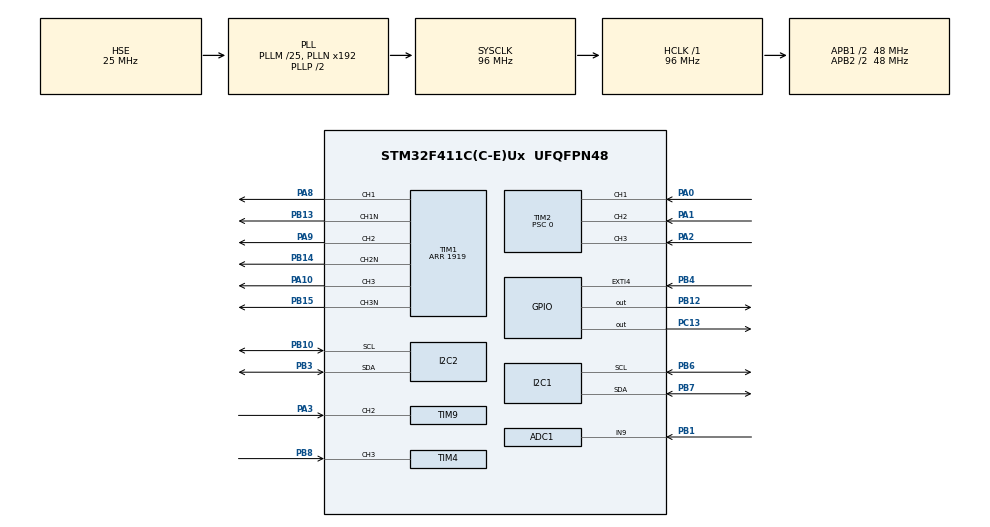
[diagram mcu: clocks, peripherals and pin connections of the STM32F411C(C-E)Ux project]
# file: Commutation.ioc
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ADC1.Channel-0\#ChannelRegularConversion=ADC_CHANNEL_9
ADC1.ExternalTrigConv=ADC_EXTERNALTRIGCONV_T3_TRGO
ADC1.NbrOfConversionFlag=1
ADC1.Rank-0\#ChannelRegularConversion=1
ADC1.SamplingTime-0\#ChannelRegularConversion=ADC_SAMPLETIME_15CYCLES
ADC1.master=1
I2C1.NoStretchMode=I2C_NOSTRETCH_DISABLE
I2C1.OwnAddress=0x10
Mcu.Family=STM32F4
Mcu.Name=STM32F411C(C-E)Ux
Mcu.Package=UFQFPN48
NVIC.ADC_IRQn=true\:0\:0\:false\:false\:true\:true\:true\:true
NVIC.EXTI4_IRQn=true\:0\:0\:false\:false\:true\:true\:true\:true
NVIC.I2C1_ER_IRQn=true\:0\:0\:false\:false\:true\:true\:true\:true
NVIC.I2C1_EV_IRQn=true\:0\:0\:false\:false\:true\:true\:true\:true
NVIC.PriorityGroup=NVIC_PRIORITYGROUP_4
NVIC.TIM1_BRK_TIM9_IRQn=true\:0\:0\:false\:false\:true\:true\:true\:true
NVIC.TIM1_TRG_COM_TIM11_IRQn=true\:0\:0\:false\:false\:true\:true\:true\:true
NVIC.TIM1_UP_TIM10_IRQn=true\:0\:0\:false\:false\:true\:true\:true\:true
NVIC.TIM2_IRQn=true\:0\:0\:false\:false\:true\:true\:true\:true
NVIC.TIM3_IRQn=true\:0\:0\:false\:false\:true\:true\:true\:true
NVIC.TIM5_IRQn=true\:0\:0\:false\:false\:true\:true\:true\:true
PA0-WKUP.GPIO_PuPd=GPIO_PULLUP
PA0-WKUP.Signal=S_TIM2_CH1_ETR
PA1.GPIO_PuPd=GPIO_PULLUP
PA1.Signal=S_TIM2_CH2
PA10.GPIO_PuPd=GPIO_NOPULL
PA10.Signal=S_TIM1_CH3
PA13.Mode=Serial_Wire
PA13.Signal=SYS_JTMS-SWDIO
PA14.Mode=Serial_Wire
PA14.Signal=SYS_JTCK-SWCLK
PA2.GPIO_PuPd=GPIO_PULLUP
PA2.Signal=S_TIM2_CH3
PA3.GPIO_PuPd=GPIO_PULLUP
PA3.Signal=S_TIM9_CH2
PA8.GPIO_PuPd=GPIO_NOPULL
PA8.Signal=S_TIM1_CH1
PA9.GPIO_PuPd=GPIO_NOPULL
PA9.Signal=S_TIM1_CH2
PB1.Signal=ADCx_IN9
PB10.GPIO_Pu=GPIO_PULLUP
PB10.Mode=I2C
PB10.Signal=I2C2_SCL
PB12.Signal=GPIO_Output
PB13.GPIO_PuPd=GPIO_NOPULL
PB13.Mode=PWM Generation1 CH1 CH1N
PB13.Signal=TIM1_CH1N
PB14.GPIO_PuPd=GPIO_NOPULL
PB14.Mode=PWM Generation2 CH2 CH2N
PB14.Signal=TIM1_CH2N
PB15.GPIO_PuPd=GPIO_NOPULL
PB15.Mode=PWM Generation3 CH3 CH3N
PB15.Signal=TIM1_CH3N
PB3.GPIO_Pu=GPIO_PULLUP
PB3.Mode=I2C
PB3.Signal=I2C2_SDA
PB4.GPIO_ModeDefaultEXTI=GPIO_MODE_IT_FALLING
PB4.GPIO_PuPd=GPIO_PULLDOWN
PB4.Signal=GPXTI4
PB6.GPIO_Pu=GPIO_PULLUP
PB6.Mode=I2C
PB6.Signal=I2C1_SCL
PB7.GPIO_Pu=GPIO_PULLUP
PB7.Mode=I2C
PB7.Signal=I2C1_SDA
PB8.Signal=S_TIM4_CH3
PC13-ANTI_TAMP.Signal=GPIO_Output
PH0\ -\ OSC_IN.Mode=HSE-External-Oscillator
PH0\ -\ OSC_IN.Signal=RCC_OSC_IN
PH1\ -\ OSC_OUT.Mode=HSE-External-Oscillator
PH1\ -\ OSC_OUT.Signal=RCC_OSC_OUT
ProjectManager.HeapSize=0x200
ProjectManager.StackSize=0x400
ProjectManager.TargetToolchain=STM32CubeIDE
RCC.48MHZClocksFreq_Value=48000000
RCC.AHBFreq_Value=96000000
RCC.APB1CLKDivider=RCC_HCLK_DIV2
RCC.APB1Freq_Value=48000000
RCC.APB1TimFreq_Value=96000000
RCC.APB2CLKDivider=RCC_HCLK_DIV2
RCC.APB2Freq_Value=48000000
RCC.APB2TimFreq_Value=96000000
RCC.CortexFreq_Value=96000000
RCC.HCLKFreq_Value=96000000
RCC.HSE_VALUE=25000000
RCC.HSI_VALUE=16000000
RCC.LSE_VALUE=32768
RCC.PLLM=25
RCC.PLLSourceVirtual=RCC_PLLSOURCE_HSE
RCC.SYSCLKFreq_VALUE=96000000
RCC.SYSCLKSource=RCC_SYSCLKSOURCE_PLLCLK
RCC.VCOOutputFreq_Value=192000000
SH.ADCx_IN9.0=ADC1_IN9,IN9
SH.S_TIM1_CH1.0=TIM1_CH1,PWM Generation1 CH1 CH1N
SH.S_TIM1_CH2.0=TIM1_CH2,PWM Generation2 CH2 CH2N
SH.S_TIM1_CH3.0=TIM1_CH3,PWM Generation3 CH3 CH3N
SH.S_TIM2_CH1_ETR.0=TIM2_CH1,Xored_Inputs_Hall_Sensor_Interface
SH.S_TIM2_CH2.0=TIM2_CH2,Xored_Inputs_Hall_Sensor_Interface
SH.S_TIM2_CH3.0=TIM2_CH3,Xored_Inputs_Hall_Sensor_Interface
SH.S_TIM4_CH3.0=TIM4_CH3,Input_Capture3_from_TI3
SH.S_TIM9_CH2.0=TIM9_CH2,Input_Capture2_from_TI2
TIM1.Channel-PWM\ Generation1\ CH1\ CH1N=TIM_CHANNEL_1
TIM1.Channel-PWM\ Generation2\ CH2\ CH2N=TIM_CHANNEL_2
TIM1.Channel-PWM\ Generation3\ CH3\ CH3N=TIM_CHANNEL_3
TIM1.Period=1919
TIM1.Pulse-PWM\ Generation1\ CH1\ CH1N=0
TIM1.Pulse-PWM\ Generation2\ CH2\ CH2N=0
TIM1.Pulse-PWM\ Generation3\ CH3\ CH3N=0
TIM2.AutoReloadPreload=TIM_AUTORELOAD_PRELOAD_DISABLE
TIM2.IC1Filter=0
TIM2.Prescaler=0
TIM3.Channel-PWM\ Generation1\ No\ Output=TIM_CHANNEL_1
TIM3.Period=959
TIM3.TIM_MasterOutputTrigger=TIM_TRGO_UPDATE
TIM4.Channel-Input_Capture3_from_TI3=TIM_CHANNEL_3
TIM5.Channel-PWM\ Generation1\ No\ Output=TIM_CHANNEL_1
TIM5.Period=960000
TIM5.Prescaler=100
TIM9.Channel-Input_Capture2_from_TI2=TIM_CHANNEL_2
TIM9.ICFilter_CH2=2
TIM9.Period=63999
TIM9.Prescaler=1499
VP_TIM1_VS_ClockSourceITR.Mode=TriggerSource_ITR0
VP_TIM1_VS_ControllerModeReset.Mode=Reset Mode
VP_TIM3_VS_no_output1.Mode=PWM Generation1 No Output
VP_TIM5_VS_no_output1.Mode=PWM Generation1 No Output
board=custom

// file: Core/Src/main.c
/* USER CODE BEGIN Header */
/**
  ******************************************************************************
  * @file           : main.c
  * @brief          : Main program body
  ******************************************************************************
  * @attention
  *
  * Copyright (c) 2024 STMicroelectronics.
  * All rights reserved.
  *
  * This software is licensed under terms that can be found in the LICENSE file
  * in the root directory of this software component.
  * If no LICENSE file comes with this software, it is provided AS-IS.
  *
  ******************************************************************************
  */
/* USER CODE END Header */
#include "main.h"
#include "adc.h"
#include "i2c.h"
#include "tim.h"
#include "gpio.h"

/* USER CODE BEGIN Includes */

#include "stm32f4xx_hal_rcc.h"

/* USER CODE END Includes */

/* USER CODE BEGIN PV */

int Buzzer = 0;

HAL_StatusTypeDef ret;

// Commutation table for motor control
// Hex values are for CCER, CCMR2 and CCMR1 in this order.
// CCER enables output while CCMRx sets PWM mode, forced active or forced inactive.
/*
uint16_t Commutation[6][3] = {
		{0x0405, 0x0858, 0x4868}, // 010 Phase 3 Low,  Phase 2 Off,  Phase 1 High
		{0x0504, 0x0868, 0x4858}, // 101 Phase 3 High, Phase 2 Off,  Phase 1 Low
		{0x0450, 0x0858, 0x6848}, // 011 Phase 3 Low,  Phase 2 High, Phase 1 Off
		{0x0054, 0x0848, 0x6858}, // 001 Phase 3 Off,  Phase 2 High, Phase 1 Low
		{0x0045, 0x0848, 0x5868}, // 110 Phase 3 Off,  Phase 2 Low,  Phase 1 High
		{0x0540, 0x0868, 0x5848}  // 100 Phase 3 High, Phase 2 Low,  Phase 1 Off
};
*/

/*
uint16_t Commutation[6][3] = {
		{0x0540, 0x0868, 0x5848}, // 100 Phase 3 High, Phase 2 Low,  Phase 1 Off
		{0x0054, 0x0848, 0x6858}, // 001 Phase 3 Off,  Phase 2 High, Phase 1 Low
		{0x0504, 0x0868, 0x4858}, // 101 Phase 3 High, Phase 2 Off,  Phase 1 Low
		{0x0405, 0x0858, 0x4868}, // 010 Phase 3 Low,  Phase 2 Off,  Phase 1 High
		{0x0045, 0x0848, 0x5868}, // 110 Phase 3 Off,  Phase 2 Low,  Phase 1 High
		{0x0450, 0x0858, 0x6848}, // 011 Phase 3 Low,  Phase 2 High, Phase 1 Off
};
*/

/*
uint16_t Commutation[6][3] = {
		{0x0504, 0x0868, 0x4858}, // 101 Phase 3 High, Phase 2 Off,  Phase 1 Low
		{0x0540, 0x0868, 0x5848}, // 100 Phase 3 High, Phase 2 Low,  Phase 1 Off
		{0x0405, 0x0858, 0x4868}, // 010 Phase 3 Low,  Phase 2 Off,  Phase 1 High
		{0x0054, 0x0848, 0x6858}, // 001 Phase 3 Off,  Phase 2 High, Phase 1 Low
		{0x0450, 0x0858, 0x6848}, // 011 Phase 3 Low,  Phase 2 High, Phase 1 Off
		{0x0045, 0x0848, 0x5868}, // 110 Phase 3 Off,  Phase 2 Low,  Phase 1 High
};
*/

/* USER CODE END PV */

void SystemClock_Config(void);
/* USER CODE BEGIN PFP */

// extern uint8_t CDC_Transmit_FS (uint8_t* buf, uint16_t len);

/* USER CODE END PFP */

int main(void)
{

  /* MCU Configuration--------------------------------------------------------*/

  /* Reset of all peripherals, Initializes the Flash interface and the Systick. */
  HAL_Init();

  /* Configure the system clock */
  SystemClock_Config();

  /* Initialize all configured peripherals */
  MX_GPIO_Init();
  MX_TIM1_Init();
  MX_TIM2_Init();
  MX_TIM9_Init();
  MX_I2C1_Init();
  MX_ADC1_Init();
  MX_I2C2_Init();
  MX_TIM4_Init();
  MX_TIM3_Init();
  MX_TIM5_Init();
  /* USER CODE BEGIN 2 */

	HAL_I2C_EnableListen_IT (&hi2c1);

    // StartupSequence(1);
    // ChangePWM();

  /* USER CODE END 2 */

  /* Infinite loop */
  /* USER CODE BEGIN WHILE */
  while (1)
  {

	  /*
	  if (Buzzer == 1) {

		  HAL_GPIO_WritePin(GPIOB, GPIO_PIN_9, 1);
		  HAL_Delay(20);
		  HAL_GPIO_WritePin(GPIOB, GPIO_PIN_9, 0);

		  Buzzer = 0;

	  }
	  */

	  /*
	  buff[0] = 0x05;
	  buff[1] = 0x00;

	  ret = HAL_I2C_Master_Transmit(&hi2c2, MCP9808_ADDR << 1, buff, 1, HAL_MAX_DELAY);
	  ret = HAL_I2C_Master_Receive(&hi2c2, MCP9808_ADDR << 1, buff, 2, HAL_MAX_DELAY);

	  Temp = ((((int16_t)buff[0] << 11) + ((int16_t)buff[1] << 3)) >> 3) / 1600.0;
	  */

	  /*
	  // Read current data from ADC.
	  HAL_ADC_Start(&hadc1);
	  HAL_ADC_PollForConversion(&hadc1, HAL_MAX_DELAY);
	  Registers[CurReg] = HAL_ADC_GetValue(&hadc1);
	  */

    /* USER CODE END WHILE */

  }
}

void SystemClock_Config(void)
{
  RCC_OscInitTypeDef RCC_OscInitStruct = {0};
  RCC_ClkInitTypeDef RCC_ClkInitStruct = {0};

  /** Configure the main internal regulator output voltage
  */
  __HAL_RCC_PWR_CLK_ENABLE();
  __HAL_PWR_VOLTAGESCALING_CONFIG(PWR_REGULATOR_VOLTAGE_SCALE1);

  /** Initializes the RCC Oscillators according to the specified parameters
  * in the RCC_OscInitTypeDef structure.
  */
  RCC_OscInitStruct.OscillatorType = RCC_OSCILLATORTYPE_HSE;
  RCC_OscInitStruct.HSEState = RCC_HSE_ON;
  RCC_OscInitStruct.PLL.PLLState = RCC_PLL_ON;
  RCC_OscInitStruct.PLL.PLLSource = RCC_PLLSOURCE_HSE;
  RCC_OscInitStruct.PLL.PLLM = 25;
  RCC_OscInitStruct.PLL.PLLN = 192;
  RCC_OscInitStruct.PLL.PLLP = RCC_PLLP_DIV2;
  RCC_OscInitStruct.PLL.PLLQ = 4;
  if (HAL_RCC_OscConfig(&RCC_OscInitStruct) != HAL_OK)
  {
    Error_Handler();
  }

  /** Initializes the CPU, AHB and APB buses clocks
  */
  RCC_ClkInitStruct.ClockType = RCC_CLOCKTYPE_HCLK|RCC_CLOCKTYPE_SYSCLK
                              |RCC_CLOCKTYPE_PCLK1|RCC_CLOCKTYPE_PCLK2;
  RCC_ClkInitStruct.SYSCLKSource = RCC_SYSCLKSOURCE_PLLCLK;
  RCC_ClkInitStruct.AHBCLKDivider = RCC_SYSCLK_DIV1;
  RCC_ClkInitStruct.APB1CLKDivider = RCC_HCLK_DIV2;
  RCC_ClkInitStruct.APB2CLKDivider = RCC_HCLK_DIV2;

  if (HAL_RCC_ClockConfig(&RCC_ClkInitStruct, FLASH_LATENCY_3) != HAL_OK)
  {
    Error_Handler();
  }
}

void Error_Handler(void)
{
  __disable_irq();
  while (1)
  {
  }
}
